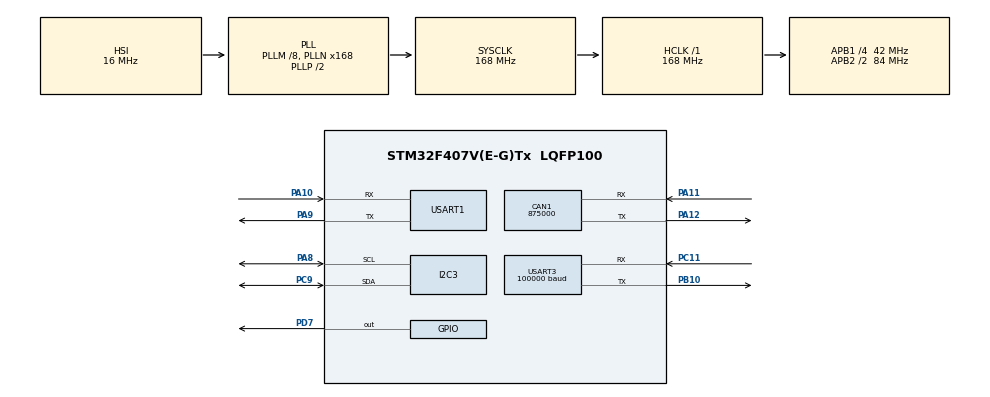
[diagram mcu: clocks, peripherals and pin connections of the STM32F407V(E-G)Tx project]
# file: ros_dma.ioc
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CAN1.CalculateBaudRate=875000
CAN1.CalculateTimeBit=1142
CAN1.CalculateTimeQuantum=380.95238095238096
Dma.Request0=USART1_RX
Dma.Request1=USART1_TX
Dma.Request2=USART3_RX
Dma.USART1_RX.0.Direction=DMA_PERIPH_TO_MEMORY
Dma.USART1_RX.0.FIFOMode=DMA_FIFOMODE_DISABLE
Dma.USART1_RX.0.Instance=DMA2_Stream2
Dma.USART1_RX.0.MemDataAlignment=DMA_MDATAALIGN_BYTE
Dma.USART1_RX.0.MemInc=DMA_MINC_ENABLE
Dma.USART1_RX.0.Mode=DMA_NORMAL
Dma.USART1_RX.0.PeriphDataAlignment=DMA_PDATAALIGN_BYTE
Dma.USART1_RX.0.PeriphInc=DMA_PINC_DISABLE
Dma.USART1_RX.0.Priority=DMA_PRIORITY_HIGH
Dma.USART1_TX.1.Direction=DMA_MEMORY_TO_PERIPH
Dma.USART1_TX.1.FIFOMode=DMA_FIFOMODE_DISABLE
Dma.USART1_TX.1.Instance=DMA2_Stream7
Dma.USART1_TX.1.MemDataAlignment=DMA_MDATAALIGN_BYTE
Dma.USART1_TX.1.MemInc=DMA_MINC_ENABLE
Dma.USART1_TX.1.Mode=DMA_NORMAL
Dma.USART1_TX.1.PeriphDataAlignment=DMA_PDATAALIGN_BYTE
Dma.USART1_TX.1.PeriphInc=DMA_PINC_DISABLE
Dma.USART1_TX.1.Priority=DMA_PRIORITY_HIGH
Dma.USART3_RX.2.Direction=DMA_PERIPH_TO_MEMORY
Dma.USART3_RX.2.FIFOMode=DMA_FIFOMODE_DISABLE
Dma.USART3_RX.2.Instance=DMA1_Stream1
Dma.USART3_RX.2.MemDataAlignment=DMA_MDATAALIGN_BYTE
Dma.USART3_RX.2.MemInc=DMA_MINC_ENABLE
Dma.USART3_RX.2.Mode=DMA_NORMAL
Dma.USART3_RX.2.PeriphDataAlignment=DMA_PDATAALIGN_BYTE
Dma.USART3_RX.2.PeriphInc=DMA_PINC_DISABLE
Dma.USART3_RX.2.Priority=DMA_PRIORITY_HIGH
Mcu.Family=STM32F4
Mcu.Name=STM32F407V(E-G)Tx
Mcu.Package=LQFP100
NVIC.CAN1_RX0_IRQn=true\:0\:0\:false\:false\:true\:true\:true\:true
NVIC.CAN1_RX1_IRQn=true\:0\:0\:false\:false\:true\:true\:true\:true
NVIC.DMA1_Stream1_IRQn=true\:0\:0\:false\:false\:true\:false\:true\:true
NVIC.DMA2_Stream2_IRQn=true\:0\:0\:false\:false\:true\:false\:true\:true
NVIC.DMA2_Stream7_IRQn=true\:0\:0\:false\:false\:true\:false\:true\:true
NVIC.PriorityGroup=NVIC_PRIORITYGROUP_4
NVIC.USART1_IRQn=true\:0\:0\:false\:false\:true\:true\:true\:true
NVIC.USART3_IRQn=true\:0\:0\:false\:false\:true\:true\:true\:true
PA10.Mode=Asynchronous
PA10.Signal=USART1_RX
PA11.Mode=CAN_Activate
PA11.Signal=CAN1_RX
PA12.Mode=CAN_Activate
PA12.Signal=CAN1_TX
PA8.Mode=I2C
PA8.Signal=I2C3_SCL
PA9.Mode=Asynchronous
PA9.Signal=USART1_TX
PB10.Mode=Asynchronous
PB10.Signal=USART3_TX
PC11.Mode=Asynchronous
PC11.Signal=USART3_RX
PC9.Mode=I2C
PC9.Signal=I2C3_SDA
PD7.Signal=GPIO_Output
PH0-OSC_IN.Mode=HSE-External-Oscillator
PH0-OSC_IN.Signal=RCC_OSC_IN
PH1-OSC_OUT.Mode=HSE-External-Oscillator
PH1-OSC_OUT.Signal=RCC_OSC_OUT
ProjectManager.HeapSize=0x200
ProjectManager.StackSize=0x400
ProjectManager.TargetToolchain=MDK-ARM V5.32
RCC.48MHZClocksFreq_Value=84000000
RCC.AHBFreq_Value=168000000
RCC.APB1CLKDivider=RCC_HCLK_DIV4
RCC.APB1Freq_Value=42000000
RCC.APB1TimFreq_Value=84000000
RCC.APB2CLKDivider=RCC_HCLK_DIV2
RCC.APB2Freq_Value=84000000
RCC.APB2TimFreq_Value=168000000
RCC.CortexFreq_Value=168000000
RCC.HCLKFreq_Value=168000000
RCC.HSE_VALUE=25000000
RCC.HSI_VALUE=16000000
RCC.LSE_VALUE=32768
RCC.PLLM=8
RCC.PLLN=168
RCC.SYSCLKFreq_VALUE=168000000
RCC.SYSCLKSource=RCC_SYSCLKSOURCE_PLLCLK
RCC.VCOOutputFreq_Value=336000000
USART1.VirtualMode=VM_ASYNC
USART3.BaudRate=100000
USART3.Mode=MODE_RX
USART3.Parity=PARITY_EVEN
USART3.VirtualMode=VM_ASYNC
board=custom

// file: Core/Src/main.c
/* USER CODE BEGIN Header */
/**
  ******************************************************************************
  * @file           : main.c
  * @brief          : Main program body
  ******************************************************************************
  * @attention
  *
  * Copyright (c) 2023 STMicroelectronics.
  * All rights reserved.
  *
  * This software is licensed under terms that can be found in the LICENSE file
  * in the root directory of this software component.
  * If no LICENSE file comes with this software, it is provided AS-IS.
  *
  ******************************************************************************
  */
/* USER CODE END Header */
#include "main.h"
#include "can.h"
#include "dma.h"
#include "i2c.h"
#include "usart.h"
#include "gpio.h"

/* USER CODE BEGIN PD */
#define send_size 256
#define rec_size 256
#define SBUS_RX_BUF_NUM 36

/* USER CODE END PD */

void SystemClock_Config(void);

/* USER CODE BEGIN 0 */
uint8_t send_data[send_size]="working working \r\n";
uint8_t rec_data[rec_size]={0};
uint8_t __full[50]="array full\r\n clear array\r\n";

static uint8_t SBUS_rx_buf[2][SBUS_RX_BUF_NUM];
/* USER CODE END 0 */

int main(void)
{

  /* MCU Configuration--------------------------------------------------------*/

  /* Reset of all peripherals, Initializes the Flash interface and the Systick. */
  HAL_Init();

  /* Configure the system clock */
  SystemClock_Config();

  /* Initialize all configured peripherals */
  MX_GPIO_Init();
  MX_DMA_Init();
  MX_USART1_UART_Init();
  MX_I2C3_Init();
  MX_CAN1_Init();
  MX_USART3_UART_Init();

  /* Infinite loop */
  while (1)
  {

    /* USER CODE BEGIN 3 */
	  HAL_GPIO_TogglePin(GPIOD, GPIO_PIN_7);
//	  HAL_UART_Transmit_DMA(&huart1, send_data, sizeof(send_data));
//	  HAL_UART_Receive_DMA(&huart1, rec_data, 256);
	  HAL_UART_Receive_DMA(&huart3, SBUS_rx_buf[0], 18);
  }
  /* USER CODE END 3 */
}

void SystemClock_Config(void)
{
  RCC_OscInitTypeDef RCC_OscInitStruct = {0};
  RCC_ClkInitTypeDef RCC_ClkInitStruct = {0};

  /** Configure the main internal regulator output voltage
  */
  __HAL_RCC_PWR_CLK_ENABLE();
  __HAL_PWR_VOLTAGESCALING_CONFIG(PWR_REGULATOR_VOLTAGE_SCALE1);

  /** Initializes the RCC Oscillators according to the specified parameters
  * in the RCC_OscInitTypeDef structure.
  */
  RCC_OscInitStruct.OscillatorType = RCC_OSCILLATORTYPE_HSI;
  RCC_OscInitStruct.HSIState = RCC_HSI_ON;
  RCC_OscInitStruct.HSICalibrationValue = RCC_HSICALIBRATION_DEFAULT;
  RCC_OscInitStruct.PLL.PLLState = RCC_PLL_ON;
  RCC_OscInitStruct.PLL.PLLSource = RCC_PLLSOURCE_HSI;
  RCC_OscInitStruct.PLL.PLLM = 8;
  RCC_OscInitStruct.PLL.PLLN = 168;
  RCC_OscInitStruct.PLL.PLLP = RCC_PLLP_DIV2;
  RCC_OscInitStruct.PLL.PLLQ = 4;
  if (HAL_RCC_OscConfig(&RCC_OscInitStruct) != HAL_OK)
  {
    Error_Handler();
  }

  /** Initializes the CPU, AHB and APB buses clocks
  */
  RCC_ClkInitStruct.ClockType = RCC_CLOCKTYPE_HCLK|RCC_CLOCKTYPE_SYSCLK
                              |RCC_CLOCKTYPE_PCLK1|RCC_CLOCKTYPE_PCLK2;
  RCC_ClkInitStruct.SYSCLKSource = RCC_SYSCLKSOURCE_PLLCLK;
  RCC_ClkInitStruct.AHBCLKDivider = RCC_SYSCLK_DIV1;
  RCC_ClkInitStruct.APB1CLKDivider = RCC_HCLK_DIV4;
  RCC_ClkInitStruct.APB2CLKDivider = RCC_HCLK_DIV2;

  if (HAL_RCC_ClockConfig(&RCC_ClkInitStruct, FLASH_LATENCY_5) != HAL_OK)
  {
    Error_Handler();
  }
}

/* USER CODE BEGIN 4 */
void HAL_UART_RxCpltCallback(UART_HandleTypeDef *huart)
{
	//只有当接收数组满了才会进入中断

	HAL_UART_Transmit_IT(&huart1, __full, sizeof(__full));//busy
}

/* USER CODE END 4 */

void Error_Handler(void)
{
  __disable_irq();
  while (1)
  {
  }
}
